# MSPM0G310X register map
Vendor: Texas Instruments; File version: This preliminary header file does not have a version number - build date: 2023-02-21 16:25:48
CPU: CM0 r0p1, little endian, MPU, no FPU, 3 interrupt priority bits
Registers are 32-bit, read-write, reset 0x0 unless marked. A register's access mark holds for its fields unless they carry their own. Offsets are from the block's base; [hi:lo] are bit positions; {n}, {i} and the like mark numbered series.

## ADC0 — PERIPHERALREGION
Base 0x40000000
Same registers: ADC1 0x40002000
0x400 FSUB_0 — Subscriber Configuration Register.
  [3:0] FSUB_0_CHANID — 0 = disconnected. 1-15 = connected to channelID = CHANID.
    0=FSUB_0_CHANID_UNCONNECTED (UNCONNECTED)
0x444 FPUB_1 — Publisher Configuration Register.
  [3:0] FPUB_1_CHANID — 0 = disconnected. 1-15 = connected to channelID = CHANID.
    0=FPUB_1_CHANID_UNCONNECTED (UNCONNECTED)
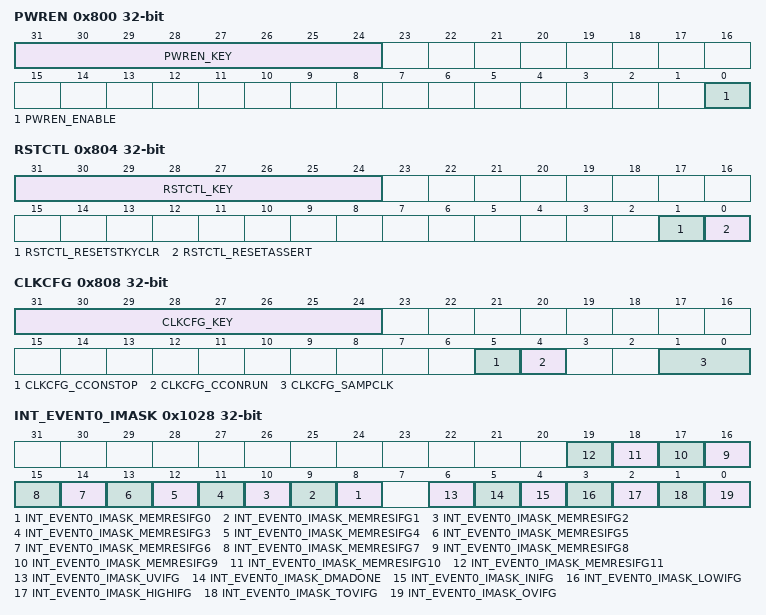
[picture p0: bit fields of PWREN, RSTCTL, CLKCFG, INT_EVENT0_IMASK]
0x800 PWREN — Power enable
  [31:24] PWREN_KEY wo — KEY to allow Power State Change
    38=PWREN_KEY_UNLOCK_W (_TO_UNLOCK_W_)
  [0] PWREN_ENABLE — Enable the power
    0=PWREN_ENABLE_DISABLE (DISABLE); 1=PWREN_ENABLE_ENABLE (ENABLE)
0x804 RSTCTL wo — Reset Control
  [31:24] RSTCTL_KEY — Unlock key
    177=RSTCTL_KEY_UNLOCK_W (_TO_UNLOCK_W_)
  [1] RSTCTL_RESETSTKYCLR — Clear the RESETSTKY bit in the STAT register
    0=RSTCTL_RESETSTKYCLR_NOP (NOP); 1=RSTCTL_RESETSTKYCLR_CLR (CLR)
  [0] RSTCTL_RESETASSERT — Assert reset to the peripheral
    0=RSTCTL_RESETASSERT_NOP (NOP); 1=RSTCTL_RESETASSERT_ASSERT (ASSERT)
0x808 CLKCFG — ADC clock configuration Register
  [31:24] CLKCFG_KEY wo — Unlock key
    169=CLKCFG_KEY_UNLOCK_W (_TO_UNLOCK_W_)
  [5] CLKCFG_CCONSTOP — CCONSTOP: Forces SYSOSC to run at base frequency when device is in STOP mode which can be used as ADC sample or conversion clock source.
    0=CLKCFG_CCONSTOP_DISABLE (DISABLE); 1=CLKCFG_CCONSTOP_ENABLE (ENABLE)
  [4] CLKCFG_CCONRUN — CCONRUN: Forces SYSOSC to run at base frequency when device is in RUN mode which can be used as ADC sample or conversion clock source.
    0=CLKCFG_CCONRUN_DISABLE (DISABLE); 1=CLKCFG_CCONRUN_ENABLE (ENABLE)
  [1:0] CLKCFG_SAMPCLK — ADC sample clock source selection.
    0=CLKCFG_SAMPCLK_SYSOSC (SYSOSC); 1=CLKCFG_SAMPCLK_ULPCLK (ULPCLK); 2=CLKCFG_SAMPCLK_HFCLK (HFCLK)
0x814 STAT ro — Status Register
  [16] STAT_RESETSTKY — This bit indicates, if the peripheral was reset, since this bit was cleared by RESETSTKYCLR in the RSTCTL register
    0=STAT_RESETSTKY_NORES (NORES); 1=STAT_RESETSTKY_RESET (RESET)
0x1020 INT_EVENT0_IIDX ro — Interrupt index
  [9:0] INT_EVENT0_IIDX_STAT — Interrupt index status
    0=INT_EVENT0_IIDX_STAT_NO_INTR (NO_INTR); 1=INT_EVENT0_IIDX_STAT_OVIFG (OVIFG); 2=INT_EVENT0_IIDX_STAT_TOVIFG (TOVIFG); 3=INT_EVENT0_IIDX_STAT_HIGHIFG (HIGHIFG); 4=INT_EVENT0_IIDX_STAT_LOWIFG (LOWIFG); 5=INT_EVENT0_IIDX_STAT_INIFG (INIFG); 6=INT_EVENT0_IIDX_STAT_DMADONE (DMADONE); 7=INT_EVENT0_IIDX_STAT_UVIFG (UVIFG); {v}=INT_EVENT0_IIDX_STAT_MEMRESIFG{v-9} (MEMRESIFG{v-9}) (v=9..32)
0x1028 INT_EVENT0_IMASK — Interrupt mask
  [n+8] INT_EVENT0_IMASK_MEMRESIFG{n} (n=0..11) — Raw interrupt status for MEMRES{n}. This bit is set to 1 when MEMRES{n} is loaded with a new conversion result. Reading MEMRES{n} register will clear this bit, or when the corresponding bit in ICLR is set to 1
    0=INT_EVENT0_IMASK_MEMRESIFG{n}_CLR (CLR); 1=INT_EVENT0_IMASK_MEMRESIFG{n}_SET (SET)
  [6] INT_EVENT0_IMASK_UVIFG — Raw interrupt flag for MEMRESx underflow. This bit is reset to 0 by IIDX read or when corresponding bit in ICLR is set to 1.
    0=INT_EVENT0_IMASK_UVIFG_CLR (CLR); 1=INT_EVENT0_IMASK_UVIFG_SET (SET)
  [5] INT_EVENT0_IMASK_DMADONE — Raw interrupt flag for DMADONE. This bit is reset to 0 by IIDX read or when corresponding bit in ICLR_EX is set to 1.
    0=INT_EVENT0_IMASK_DMADONE_CLR (CLR); 1=INT_EVENT0_IMASK_DMADONE_SET (SET)
  [4] INT_EVENT0_IMASK_INIFG — Mask INIFG in MIS_EX register.
    0=INT_EVENT0_IMASK_INIFG_CLR (CLR); 1=INT_EVENT0_IMASK_INIFG_SET (SET)
  [3] INT_EVENT0_IMASK_LOWIFG — Raw interrupt flag for the MEMRESx result register being below than the WCLOWx threshold of the window comparator. This bit is reset to 0 by IIDX read or when corresponding bit in ICLR_EX is set to 1.
    0=INT_EVENT0_IMASK_LOWIFG_CLR (CLR); 1=INT_EVENT0_IMASK_LOWIFG_SET (SET)
  [2] INT_EVENT0_IMASK_HIGHIFG — Raw interrupt flag for the MEMRESx result register being higher than the WCHIGHx threshold of the window comparator. This bit is reset to 0 by IIDX read or when corresponding bit in ICLR_EX is set to 1.
    0=INT_EVENT0_IMASK_HIGHIFG_CLR (CLR); 1=INT_EVENT0_IMASK_HIGHIFG_SET (SET)
  [1] INT_EVENT0_IMASK_TOVIFG — Raw interrupt flag for sequence conversion timeout overflow. This bit is reset to 0 by IIDX read or when corresponding bit in ICLR_EX is set to 1.
    0=INT_EVENT0_IMASK_TOVIFG_CLR (CLR); 1=INT_EVENT0_IMASK_TOVIFG_SET (SET)
  [0] INT_EVENT0_IMASK_OVIFG — Raw interrupt flag for MEMRESx overflow. This bit is reset to 0 by IIDX read or when corresponding bit in ICLR_EX is set to 1.
    0=INT_EVENT0_IMASK_OVIFG_CLR (CLR); 1=INT_EVENT0_IMASK_OVIFG_SET (SET)
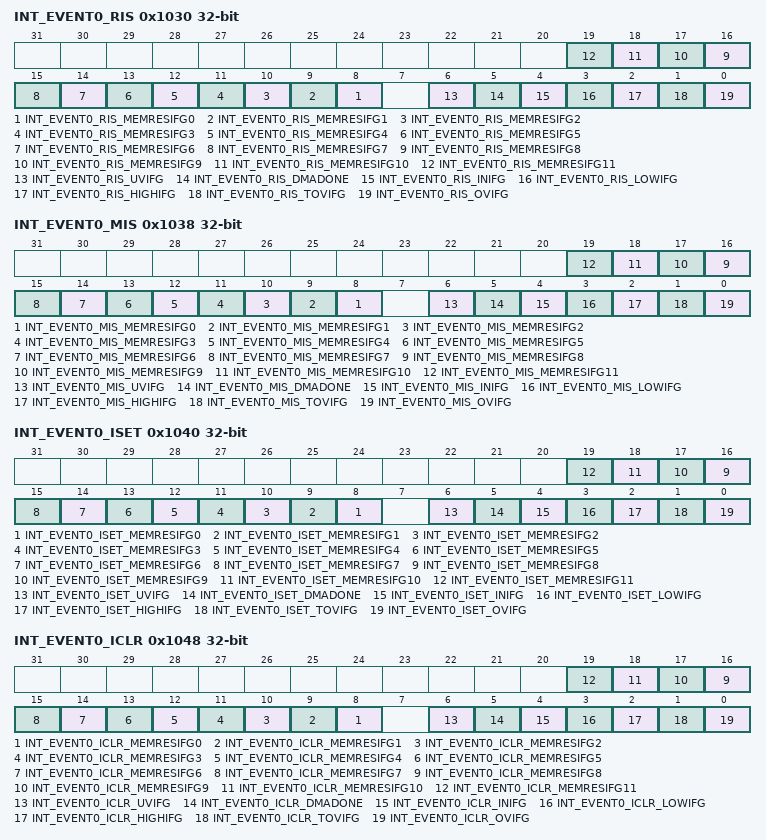
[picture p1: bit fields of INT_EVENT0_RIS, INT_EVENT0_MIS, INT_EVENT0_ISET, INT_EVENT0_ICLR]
0x1030 INT_EVENT0_RIS ro — Raw interrupt status
  [n+8] INT_EVENT0_RIS_MEMRESIFG{n} (n=0..11) — Raw interrupt status for MEMRES{n}. This bit is set to 1 when MEMRES{n} is loaded with a new conversion result. Reading MEMRES{n} register will clear this bit, or when the corresponding bit in ICLR is set to 1
    0=INT_EVENT0_RIS_MEMRESIFG{n}_CLR (CLR); 1=INT_EVENT0_RIS_MEMRESIFG{n}_SET (SET)
  [6] INT_EVENT0_RIS_UVIFG — Raw interrupt flag for MEMRESx underflow. This bit is reset to 0 by IIDX read or when corresponding bit in ICLR is set to 1.
    0=INT_EVENT0_RIS_UVIFG_CLR (CLR); 1=INT_EVENT0_RIS_UVIFG_SET (SET)
  [5] INT_EVENT0_RIS_DMADONE — Raw interrupt flag for DMADONE. This bit is reset to 0 by IIDX read or when corresponding bit in ICLR_EX is set to 1.
    0=INT_EVENT0_RIS_DMADONE_CLR (CLR); 1=INT_EVENT0_RIS_DMADONE_SET (SET)
  [4] INT_EVENT0_RIS_INIFG — Mask INIFG in MIS_EX register.
    0=INT_EVENT0_RIS_INIFG_CLR (CLR); 1=INT_EVENT0_RIS_INIFG_SET (SET)
  [3] INT_EVENT0_RIS_LOWIFG — Raw interrupt flag for the MEMRESx result register being below than the WCLOWx threshold of the window comparator. This bit is reset to 0 by IIDX read or when corresponding bit in ICLR_EX is set to 1.
    0=INT_EVENT0_RIS_LOWIFG_CLR (CLR); 1=INT_EVENT0_RIS_LOWIFG_SET (SET)
  [2] INT_EVENT0_RIS_HIGHIFG — Raw interrupt flag for the MEMRESx result register being higher than the WCHIGHx threshold of the window comparator. This bit is reset to 0 by IIDX read or when corresponding bit in ICLR_EX is set to 1.
    0=INT_EVENT0_RIS_HIGHIFG_CLR (CLR); 1=INT_EVENT0_RIS_HIGHIFG_SET (SET)
  [1] INT_EVENT0_RIS_TOVIFG — Raw interrupt flag for sequence conversion trigger overflow. This bit is reset to 0 by IIDX read or when corresponding bit in ICLR_EX is set to 1.
    0=INT_EVENT0_RIS_TOVIFG_CLR (CLR); 1=INT_EVENT0_RIS_TOVIFG_SET (SET)
  [0] INT_EVENT0_RIS_OVIFG — Raw interrupt flag for MEMRESx overflow. This bit is reset to 0 by IIDX read or when corresponding bit in ICLR_EX is set to 1.
    0=INT_EVENT0_RIS_OVIFG_CLR (CLR); 1=INT_EVENT0_RIS_OVIFG_SET (SET)
0x1038 INT_EVENT0_MIS ro — Masked interrupt status
  [n+8] INT_EVENT0_MIS_MEMRESIFG{n} (n=0..11) — Raw interrupt status for MEMRES{n}. This bit is set to 1 when MEMRES{n} is loaded with a new conversion result. Reading MEMRES{n} register will clear this bit, or when the corresponding bit in ICLR is set to 1
    0=INT_EVENT0_MIS_MEMRESIFG{n}_CLR (CLR); 1=INT_EVENT0_MIS_MEMRESIFG{n}_SET (SET)
  [6] INT_EVENT0_MIS_UVIFG — Raw interrupt flag for MEMRESx underflow. This bit is reset to 0 by IIDX read or when corresponding bit in ICLR is set to 1.
    0=INT_EVENT0_MIS_UVIFG_CLR (CLR); 1=INT_EVENT0_MIS_UVIFG_SET (SET)
  [5] INT_EVENT0_MIS_DMADONE — Raw interrupt flag for DMADONE. This bit is reset to 0 by IIDX read or when corresponding bit in ICLR_EX is set to 1.
    0=INT_EVENT0_MIS_DMADONE_CLR (CLR); 1=INT_EVENT0_MIS_DMADONE_SET (SET)
  [4] INT_EVENT0_MIS_INIFG — Mask INIFG in MIS_EX register.
    0=INT_EVENT0_MIS_INIFG_CLR (CLR); 1=INT_EVENT0_MIS_INIFG_SET (SET)
  [3] INT_EVENT0_MIS_LOWIFG — Raw interrupt flag for the MEMRESx result register being below than the WCLOWx threshold of the window comparator. This bit is reset to 0 by IIDX read or when corresponding bit in ICLR_EX is set to 1.
    0=INT_EVENT0_MIS_LOWIFG_CLR (CLR); 1=INT_EVENT0_MIS_LOWIFG_SET (SET)
  [2] INT_EVENT0_MIS_HIGHIFG — Raw interrupt flag for the MEMRESx result register being higher than the WCHIGHx threshold of the window comparator. This bit is reset to 0 by IIDX read or when corresponding bit in ICLR_EX is set to 1.
    0=INT_EVENT0_MIS_HIGHIFG_CLR (CLR); 1=INT_EVENT0_MIS_HIGHIFG_SET (SET)
  [1] INT_EVENT0_MIS_TOVIFG — Raw interrupt flag for sequence conversion timeout overflow. This bit is reset to 0 by IIDX read or when corresponding bit in ICLR_EX is set to 1.
    0=INT_EVENT0_MIS_TOVIFG_CLR (CLR); 1=INT_EVENT0_MIS_TOVIFG_SET (SET)
  [0] INT_EVENT0_MIS_OVIFG — Raw interrupt flag for MEMRESx overflow. This bit is reset to 0 by IIDX read or when corresponding bit in ICLR_EX is set to 1.
    0=INT_EVENT0_MIS_OVIFG_CLR (CLR); 1=INT_EVENT0_MIS_OVIFG_SET (SET)
0x1040 INT_EVENT0_ISET wo — Interrupt set
  [n+8] INT_EVENT0_ISET_MEMRESIFG{n} (n=0..11) — Raw interrupt status for MEMRES{n}. This bit is set to 1 when MEMRES{n} is loaded with a new conversion result. Reading MEMRES{n} register will clear this bit, or when the corresponding bit in ICLR is set to 1
    0=INT_EVENT0_ISET_MEMRESIFG{n}_NO_EFFECT (NO_EFFECT); 1=INT_EVENT0_ISET_MEMRESIFG{n}_SET (SET)
  [6] INT_EVENT0_ISET_UVIFG — Raw interrupt flag for MEMRESx underflow. This bit is reset to 0 by IIDX read or when corresponding bit in ICLR_EX is set to 1.
    0=INT_EVENT0_ISET_UVIFG_NO_EFFECT (NO_EFFECT); 1=INT_EVENT0_ISET_UVIFG_SET (SET)
  [5] INT_EVENT0_ISET_DMADONE — Raw interrupt flag for DMADONE. This bit is reset to 0 by IIDX read or when corresponding bit in ICLR_EX is set to 1.
    0=INT_EVENT0_ISET_DMADONE_NO_EFFECT (NO_EFFECT); 1=INT_EVENT0_ISET_DMADONE_SET (SET)
  [4] INT_EVENT0_ISET_INIFG — Mask INIFG in MIS_EX register.
    0=INT_EVENT0_ISET_INIFG_NO_EFFECT (NO_EFFECT); 1=INT_EVENT0_ISET_INIFG_SET (SET)
  [3] INT_EVENT0_ISET_LOWIFG — Raw interrupt flag for the MEMRESx result register being below than the WCLOWx threshold of the window comparator. This bit is reset to 0 by IIDX read or when corresponding bit in ICLR_EX is set to 1.
    0=INT_EVENT0_ISET_LOWIFG_NO_EFFECT (NO_EFFECT); 1=INT_EVENT0_ISET_LOWIFG_SET (SET)
  [2] INT_EVENT0_ISET_HIGHIFG — Raw interrupt flag for the MEMRESx result register being higher than the WCHIGHx threshold of the window comparator. This bit is reset to 0 by IIDX read or when corresponding bit in ICLR_EX is set to 1.
    0=INT_EVENT0_ISET_HIGHIFG_NO_EFFECT (NO_EFFECT); 1=INT_EVENT0_ISET_HIGHIFG_SET (SET)
  [1] INT_EVENT0_ISET_TOVIFG — Raw interrupt flag for sequence conversion timeout overflow. This bit is reset to 0 by IIDX read or when corresponding bit in ICLR_EX is set to 1.
    0=INT_EVENT0_ISET_TOVIFG_NO_EFFECT (NO_EFFECT); 1=INT_EVENT0_ISET_TOVIFG_SET (SET)
  [0] INT_EVENT0_ISET_OVIFG — Raw interrupt flag for MEMRESx overflow. This bit is reset to 0 by IIDX read or when corresponding bit in ICLR_EX is set to 1.
    0=INT_EVENT0_ISET_OVIFG_NO_EFFECT (NO_EFFECT); 1=INT_EVENT0_ISET_OVIFG_SET (SET)
0x1048 INT_EVENT0_ICLR wo — Interrupt clear
  [n+8] INT_EVENT0_ICLR_MEMRESIFG{n} (n=0..11) — Raw interrupt status for MEMRES{n}. This bit is set to 1 when MEMRES{n} is loaded with a new conversion result. Reading MEMRES{n} register will clear this bit, or when the corresponding bit in ICLR is set to 1
    0=INT_EVENT0_ICLR_MEMRESIFG{n}_NO_EFFECT (NO_EFFECT); 1=INT_EVENT0_ICLR_MEMRESIFG{n}_CLR (CLR)
  [6] INT_EVENT0_ICLR_UVIFG — Raw interrupt flag for MEMRESx underflow. This bit is reset to 0 by IIDX read or when corresponding bit in ICLR_EX is set to 1.
    0=INT_EVENT0_ICLR_UVIFG_NO_EFFECT (NO_EFFECT); 1=INT_EVENT0_ICLR_UVIFG_CLR (CLR)
  [5] INT_EVENT0_ICLR_DMADONE — Raw interrupt flag for DMADONE. This bit is reset to 0 by IIDX read or when corresponding bit in ICLR_EX is set to 1.
    0=INT_EVENT0_ICLR_DMADONE_NO_EFFECT (NO_EFFECT); 1=INT_EVENT0_ICLR_DMADONE_CLR (CLR)
  [4] INT_EVENT0_ICLR_INIFG — Mask INIFG in MIS_EX register.
    0=INT_EVENT0_ICLR_INIFG_NO_EFFECT (NO_EFFECT); 1=INT_EVENT0_ICLR_INIFG_CLR (CLR)
  [3] INT_EVENT0_ICLR_LOWIFG — Raw interrupt flag for the MEMRESx result register being below than the WCLOWx threshold of the window comparator. This bit is reset to 0 by IIDX read or when corresponding bit in ICLR_EX is set to 1.
    0=INT_EVENT0_ICLR_LOWIFG_NO_EFFECT (NO_EFFECT); 1=INT_EVENT0_ICLR_LOWIFG_CLR (CLR)
  [2] INT_EVENT0_ICLR_HIGHIFG — Raw interrupt flag for the MEMRESx result register being higher than the WCHIGHx threshold of the window comparator. This bit is reset to 0 by IIDX read or when corresponding bit in ICLR_EX is set to 1.
    0=INT_EVENT0_ICLR_HIGHIFG_NO_EFFECT (NO_EFFECT); 1=INT_EVENT0_ICLR_HIGHIFG_CLR (CLR)
  [1] INT_EVENT0_ICLR_TOVIFG — Raw interrupt flag for sequence conversion timeout overflow. This bit is reset to 0 by IIDX read or when corresponding bit in ICLR_EX is set to 1.
    0=INT_EVENT0_ICLR_TOVIFG_NO_EFFECT (NO_EFFECT); 1=INT_EVENT0_ICLR_TOVIFG_CLR (CLR)
  [0] INT_EVENT0_ICLR_OVIFG — Raw interrupt flag for MEMRESx overflow. This bit is reset to 0 by IIDX read or when corresponding bit in ICLR_EX is set to 1.
    0=INT_EVENT0_ICLR_OVIFG_NO_EFFECT (NO_EFFECT); 1=INT_EVENT0_ICLR_OVIFG_CLR (CLR)
0x1050 INT_EVENT1_IIDX ro — Interrupt index
  [9:0] INT_EVENT1_IIDX_STAT — Interrupt index status
    0=INT_EVENT1_IIDX_STAT_NO_INTR (NO_INTR); 3=INT_EVENT1_IIDX_STAT_HIGHIFG (HIGHIFG); 4=INT_EVENT1_IIDX_STAT_LOWIFG (LOWIFG); 5=INT_EVENT1_IIDX_STAT_INIFG (INIFG); 9=INT_EVENT1_IIDX_STAT_MEMRESIFG0 (MEMRESIFG0)
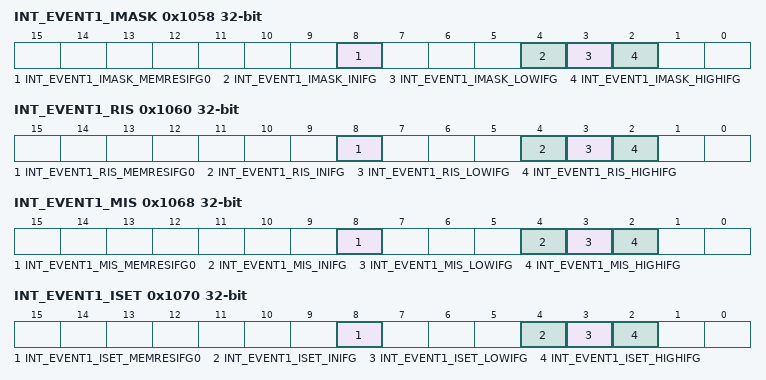
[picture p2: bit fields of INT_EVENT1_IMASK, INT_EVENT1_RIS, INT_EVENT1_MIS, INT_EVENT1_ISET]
0x1058 INT_EVENT1_IMASK — Interrupt mask
  [8] INT_EVENT1_IMASK_MEMRESIFG0 — Raw interrupt status for MEMRES0. This bit is set to 1 when MEMRES0 is loaded with a new conversion result. Reading MEMRES0 register will clear this bit, or when the corresponding bit in ICLR is set to 1
    0=INT_EVENT1_IMASK_MEMRESIFG0_CLR (CLR); 1=INT_EVENT1_IMASK_MEMRESIFG0_SET (SET)
  [4] INT_EVENT1_IMASK_INIFG — Mask INIFG in MIS_EX register.
    0=INT_EVENT1_IMASK_INIFG_CLR (CLR); 1=INT_EVENT1_IMASK_INIFG_SET (SET)
  [3] INT_EVENT1_IMASK_LOWIFG — Raw interrupt flag for the MEMRESx result register being below than the WCLOWx threshold of the window comparator. This bit is reset to 0 by IIDX read or when corresponding bit in ICLR_EX is set to 1.
    0=INT_EVENT1_IMASK_LOWIFG_CLR (CLR); 1=INT_EVENT1_IMASK_LOWIFG_SET (SET)
  [2] INT_EVENT1_IMASK_HIGHIFG — Raw interrupt flag for the MEMRESx result register being higher than the WCHIGHx threshold of the window comparator. This bit is reset to 0 by IIDX read or when corresponding bit in ICLR_EX is set to 1.
    0=INT_EVENT1_IMASK_HIGHIFG_CLR (CLR); 1=INT_EVENT1_IMASK_HIGHIFG_SET (SET)
0x1060 INT_EVENT1_RIS ro — Raw interrupt status
  [8] INT_EVENT1_RIS_MEMRESIFG0 — Raw interrupt status for MEMRES0. This bit is set to 1 when MEMRES0 is loaded with a new conversion result. Reading MEMRES0 register will clear this bit, or when the corresponding bit in ICLR is set to 1
    0=INT_EVENT1_RIS_MEMRESIFG0_CLR (CLR); 1=INT_EVENT1_RIS_MEMRESIFG0_SET (SET)
  [4] INT_EVENT1_RIS_INIFG — Mask INIFG in MIS_EX register.
    0=INT_EVENT1_RIS_INIFG_CLR (CLR); 1=INT_EVENT1_RIS_INIFG_SET (SET)
  [3] INT_EVENT1_RIS_LOWIFG — Raw interrupt flag for the MEMRESx result register being below than the WCLOWx threshold of the window comparator. This bit is reset to 0 by IIDX read or when corresponding bit in ICLR_EX is set to 1.
    0=INT_EVENT1_RIS_LOWIFG_CLR (CLR); 1=INT_EVENT1_RIS_LOWIFG_SET (SET)
  [2] INT_EVENT1_RIS_HIGHIFG — Raw interrupt flag for the MEMRESx result register being higher than the WCHIGHx threshold of the window comparator. This bit is reset to 0 by IIDX read or when corresponding bit in ICLR_EX is set to 1.
    0=INT_EVENT1_RIS_HIGHIFG_CLR (CLR); 1=INT_EVENT1_RIS_HIGHIFG_SET (SET)
0x1068 INT_EVENT1_MIS ro — Masked interrupt status
  [8] INT_EVENT1_MIS_MEMRESIFG0 — Raw interrupt status for MEMRES0. This bit is set to 1 when MEMRES0 is loaded with a new conversion result. Reading MEMRES0 register will clear this bit, or when the corresponding bit in ICLR is set to 1
    0=INT_EVENT1_MIS_MEMRESIFG0_CLR (CLR); 1=INT_EVENT1_MIS_MEMRESIFG0_SET (SET)
  [4] INT_EVENT1_MIS_INIFG — Mask INIFG in MIS_EX register.
    0=INT_EVENT1_MIS_INIFG_CLR (CLR); 1=INT_EVENT1_MIS_INIFG_SET (SET)
  [3] INT_EVENT1_MIS_LOWIFG — Raw interrupt flag for the MEMRESx result register being below than the WCLOWx threshold of the window comparator. This bit is reset to 0 by IIDX read or when corresponding bit in ICLR_EX is set to 1.
    0=INT_EVENT1_MIS_LOWIFG_CLR (CLR); 1=INT_EVENT1_MIS_LOWIFG_SET (SET)
  [2] INT_EVENT1_MIS_HIGHIFG — Raw interrupt flag for the MEMRESx result register being higher than the WCHIGHx threshold of the window comparator. This bit is reset to 0 by IIDX read or when corresponding bit in ICLR_EX is set to 1.
    0=INT_EVENT1_MIS_HIGHIFG_CLR (CLR); 1=INT_EVENT1_MIS_HIGHIFG_SET (SET)
0x1070 INT_EVENT1_ISET wo — Interrupt set
  [8] INT_EVENT1_ISET_MEMRESIFG0 — Raw interrupt status for MEMRES0. This bit is set to 1 when MEMRES0 is loaded with a new conversion result. Reading MEMRES0 register will clear this bit, or when the corresponding bit in ICLR is set to 1
    0=INT_EVENT1_ISET_MEMRESIFG0_NO_EFFECT (NO_EFFECT); 1=INT_EVENT1_ISET_MEMRESIFG0_SET (SET)
  [4] INT_EVENT1_ISET_INIFG — Mask INIFG in MIS_EX register.
    0=INT_EVENT1_ISET_INIFG_NO_EFFECT (NO_EFFECT); 1=INT_EVENT1_ISET_INIFG_SET (SET)
  [3] INT_EVENT1_ISET_LOWIFG — Raw interrupt flag for the MEMRESx result register being below than the WCLOWx threshold of the window comparator. This bit is reset to 0 by IIDX read or when corresponding bit in ICLR_EX is set to 1.
    0=INT_EVENT1_ISET_LOWIFG_NO_EFFECT (NO_EFFECT); 1=INT_EVENT1_ISET_LOWIFG_SET (SET)
  [2] INT_EVENT1_ISET_HIGHIFG — Raw interrupt flag for the MEMRESx result register being higher than the WCHIGHx threshold of the window comparator. This bit is reset to 0 by IIDX read or when corresponding bit in ICLR_EX is set to 1.
    0=INT_EVENT1_ISET_HIGHIFG_NO_EFFECT (NO_EFFECT); 1=INT_EVENT1_ISET_HIGHIFG_SET (SET)
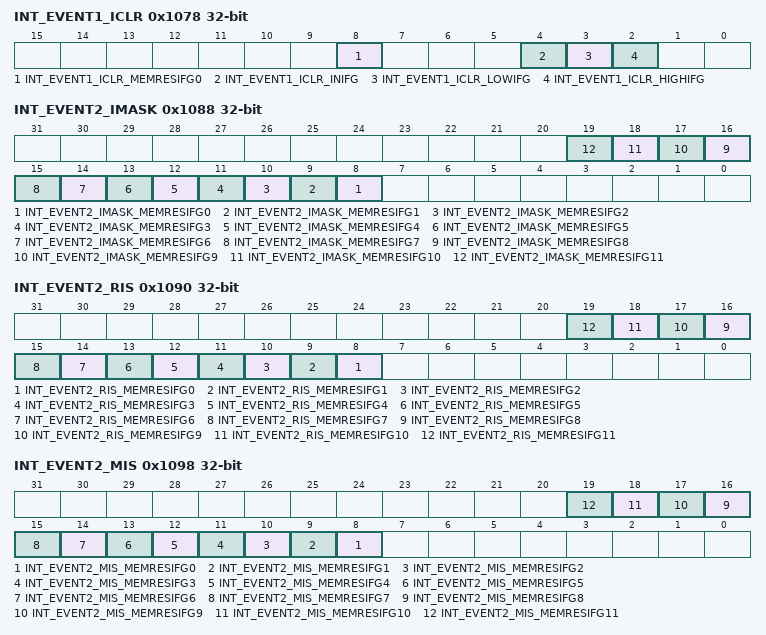
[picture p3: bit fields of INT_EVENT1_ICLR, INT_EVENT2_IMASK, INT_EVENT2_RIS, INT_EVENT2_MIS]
0x1078 INT_EVENT1_ICLR wo — Interrupt clear
  [8] INT_EVENT1_ICLR_MEMRESIFG0 — Raw interrupt status for MEMRES0. This bit is set to 1 when MEMRES0 is loaded with a new conversion result. Reading MEMRES0 register will clear this bit, or when the corresponding bit in ICLR is set to 1
    0=INT_EVENT1_ICLR_MEMRESIFG0_NO_EFFECT (NO_EFFECT); 1=INT_EVENT1_ICLR_MEMRESIFG0_CLR (CLR)
  [4] INT_EVENT1_ICLR_INIFG — Mask INIFG in MIS_EX register.
    0=INT_EVENT1_ICLR_INIFG_NO_EFFECT (NO_EFFECT); 1=INT_EVENT1_ICLR_INIFG_CLR (CLR)
  [3] INT_EVENT1_ICLR_LOWIFG — Raw interrupt flag for the MEMRESx result register being below than the WCLOWx threshold of the window comparator. This bit is reset to 0 by IIDX read or when corresponding bit in ICLR_EX is set to 1.
    0=INT_EVENT1_ICLR_LOWIFG_NO_EFFECT (NO_EFFECT); 1=INT_EVENT1_ICLR_LOWIFG_CLR (CLR)
  [2] INT_EVENT1_ICLR_HIGHIFG — Raw interrupt flag for the MEMRESx result register being higher than the WCHIGHx threshold of the window comparator. This bit is reset to 0 by IIDX read or when corresponding bit in ICLR_EX is set to 1.
    0=INT_EVENT1_ICLR_HIGHIFG_NO_EFFECT (NO_EFFECT); 1=INT_EVENT1_ICLR_HIGHIFG_CLR (CLR)
0x1080 INT_EVENT2_IIDX ro — Interrupt index
  [9:0] INT_EVENT2_IIDX_STAT — Interrupt index status
    0=INT_EVENT2_IIDX_STAT_NO_INTR (NO_INTR); {v}=INT_EVENT2_IIDX_STAT_MEMRESIFG{v-9} (MEMRESIFG{v-9}) (v=9..32)
0x1088 INT_EVENT2_IMASK — Interrupt mask extension
  [n+8] INT_EVENT2_IMASK_MEMRESIFG{n} (n=0..11) — Raw interrupt status for MEMRES{n}. This bit is set to 1 when MEMRES{n} is loaded with a new conversion result. Reading MEMRES{n} register will clear this bit, or when the corresponding bit in ICLR is set to 1
    0=INT_EVENT2_IMASK_MEMRESIFG{n}_CLR (CLR); 1=INT_EVENT2_IMASK_MEMRESIFG{n}_SET (SET)
0x1090 INT_EVENT2_RIS ro — Raw interrupt status extension
  [n+8] INT_EVENT2_RIS_MEMRESIFG{n} (n=0..11) — Raw interrupt status for MEMRES{n}. This bit is set to 1 when MEMRES{n} is loaded with a new conversion result. Reading MEMRES{n} register will clear this bit, or when the corresponding bit in ICLR is set to 1
    0=INT_EVENT2_RIS_MEMRESIFG{n}_CLR (CLR); 1=INT_EVENT2_RIS_MEMRESIFG{n}_SET (SET)
0x1098 INT_EVENT2_MIS ro — Masked interrupt status extension
  [n+8] INT_EVENT2_MIS_MEMRESIFG{n} (n=0..11) — Raw interrupt status for MEMRES{n}. This bit is set to 1 when MEMRES{n} is loaded with a new conversion result. Reading MEMRES{n} register will clear this bit, or when the corresponding bit in ICLR is set to 1
    0=INT_EVENT2_MIS_MEMRESIFG{n}_CLR (CLR); 1=INT_EVENT2_MIS_MEMRESIFG{n}_SET (SET)
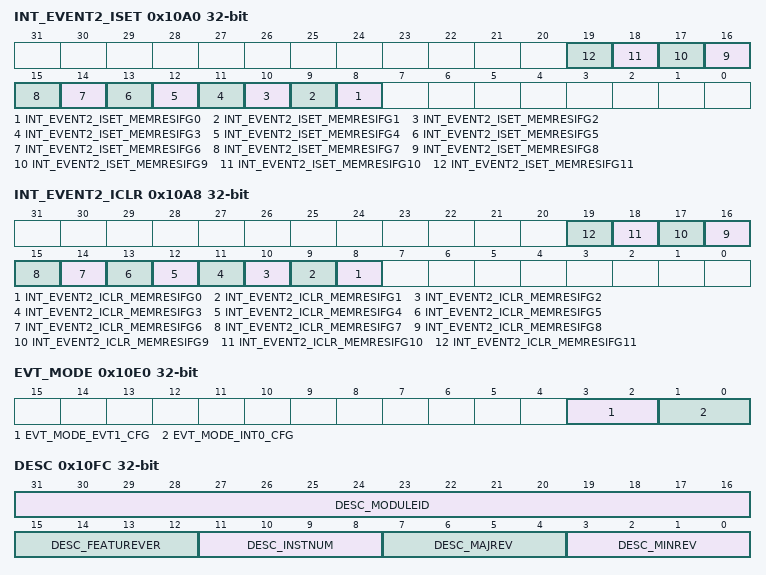
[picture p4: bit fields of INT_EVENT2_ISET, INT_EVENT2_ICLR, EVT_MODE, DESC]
0x10A0 INT_EVENT2_ISET wo — Interrupt set extension
  [n+8] INT_EVENT2_ISET_MEMRESIFG{n} (n=0..11) — Raw interrupt status for MEMRES{n}. This bit is set to 1 when MEMRES{n} is loaded with a new conversion result. Reading MEMRES{n} register will clear this bit, or when the corresponding bit in ICLR is set to 1
    0=INT_EVENT2_ISET_MEMRESIFG{n}_NO_EFFECT (NO_EFFECT); 1=INT_EVENT2_ISET_MEMRESIFG{n}_SET (SET)
0x10A8 INT_EVENT2_ICLR wo — Interrupt clear extension
  [n+8] INT_EVENT2_ICLR_MEMRESIFG{n} (n=0..11) — Raw interrupt status for MEMRES{n}. This bit is set to 1 when MEMRES{n} is loaded with a new conversion result. Reading MEMRES{n} register will clear this bit, or when the corresponding bit in ICLR is set to 1
    0=INT_EVENT2_ICLR_MEMRESIFG{n}_NO_EFFECT (NO_EFFECT); 1=INT_EVENT2_ICLR_MEMRESIFG{n}_CLR (CLR)
0x10E0 EVT_MODE ro — Event Mode
  [3:2] EVT_MODE_EVT1_CFG — Event line mode select for event corresponding to IPSTANDARD.INT_EVENT1
    0=EVT_MODE_EVT1_CFG_DISABLE (DISABLE); 1=EVT_MODE_EVT1_CFG_SOFTWARE (SOFTWARE); 2=EVT_MODE_EVT1_CFG_HARDWARE (HARDWARE)
  [1:0] EVT_MODE_INT0_CFG — Event line mode select for event corresponding to IPSTANDARD.INT_EVENT0
    0=EVT_MODE_INT0_CFG_DISABLE (DISABLE); 1=EVT_MODE_INT0_CFG_SOFTWARE (SOFTWARE); 2=EVT_MODE_INT0_CFG_HARDWARE (HARDWARE)
0x10FC DESC ro — Module Description
  [31:16] DESC_MODULEID — Module identification contains a unique peripheral identification number. The assignments are maintained in a central database for all of the platform modules to ensure uniqueness.
  [15:12] DESC_FEATUREVER — Feature Set for the module *instance*
  [11:8] DESC_INSTNUM — Instance Number within the device. This will be a parameter to the RTL for modules that can have multiple instances
  [7:4] DESC_MAJREV — Major rev of the IP
  [3:0] DESC_MINREV — Minor rev of the IP
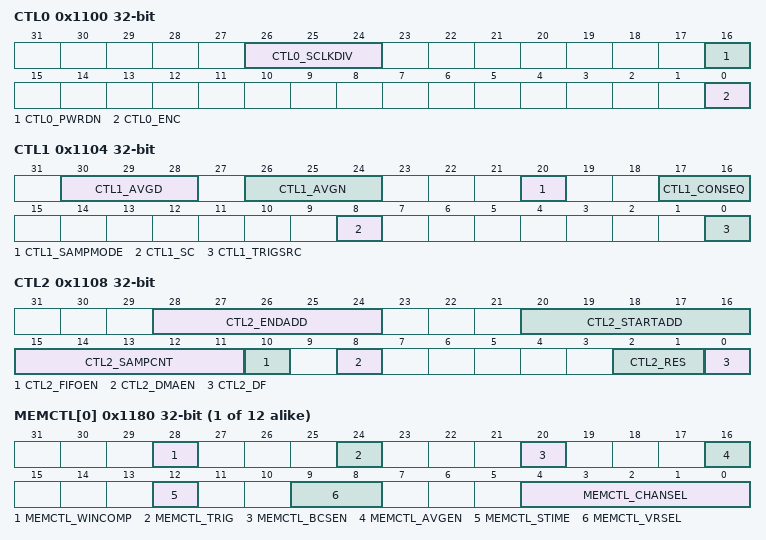
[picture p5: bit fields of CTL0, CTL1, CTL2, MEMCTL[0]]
0x1100 CTL0 — Control Register 0
  [26:24] CTL0_SCLKDIV — Sample clock divider
    0=CTL0_SCLKDIV_DIV_BY_1 (DIV_BY_1); 1=CTL0_SCLKDIV_DIV_BY_2 (DIV_BY_2); 2=CTL0_SCLKDIV_DIV_BY_4 (DIV_BY_4); 3=CTL0_SCLKDIV_DIV_BY_8 (DIV_BY_8); 4=CTL0_SCLKDIV_DIV_BY_16 (DIV_BY_16); 5=CTL0_SCLKDIV_DIV_BY_24 (DIV_BY_24); 6=CTL0_SCLKDIV_DIV_BY_32 (DIV_BY_32); 7=CTL0_SCLKDIV_DIV_BY_48 (DIV_BY_48)
  [16] CTL0_PWRDN — Power down policy
    0=CTL0_PWRDN_AUTO (AUTO); 1=CTL0_PWRDN_MANUAL (MANUAL)
  [0] CTL0_ENC — Enable conversion
    0=CTL0_ENC_OFF (OFF); 1=CTL0_ENC_ON (ON)
0x1104 CTL1 — Control Register 1
  [30:28] CTL1_AVGD — Hardware averager denominator. The number to divide the accumulated value by (this is a shift). Note result register is maximum of 16-bits long so if not shifted appropirately result will be truncated.
    {v}=CTL1_AVGD_SHIFT{v} (SHIFT{v}) (v=0..7)
  [26:24] CTL1_AVGN — Hardware averager numerator. Selects number of conversions to accumulate for current MEMCTLx and then it is divided by AVGD. Result will be stored in MEMRESx.
    0=CTL1_AVGN_DISABLE (DISABLE); 1=CTL1_AVGN_AVG_2 (AVG_2); 2=CTL1_AVGN_AVG_4 (AVG_4); 3=CTL1_AVGN_AVG_8 (AVG_8); 4=CTL1_AVGN_AVG_16 (AVG_16); 5=CTL1_AVGN_AVG_32 (AVG_32); 6=CTL1_AVGN_AVG_64 (AVG_64); 7=CTL1_AVGN_AVG_128 (AVG_128)
  [20] CTL1_SAMPMODE — Sample mode. This bit selects the source of the sampling signal. MANUAL option is not valid when TRIGSRC is selected as hardware event trigger.
    0=CTL1_SAMPMODE_AUTO (AUTO); 1=CTL1_SAMPMODE_MANUAL (MANUAL)
  [17:16] CTL1_CONSEQ — Conversion sequence mode
    0=CTL1_CONSEQ_SINGLE (SINGLE); 1=CTL1_CONSEQ_SEQUENCE (SEQUENCE); 2=CTL1_CONSEQ_REPEATSINGLE (REPEATSINGLE); 3=CTL1_CONSEQ_REPEATSEQUENCE (REPEATSEQUENCE)
  [8] CTL1_SC — Start of conversion
    0=CTL1_SC_STOP (STOP); 1=CTL1_SC_START (START)
  [0] CTL1_TRIGSRC — Sample trigger source
    0=CTL1_TRIGSRC_SOFTWARE (SOFTWARE); 1=CTL1_TRIGSRC_EVENT (EVENT)
0x1108 CTL2 — Control Register 2
  [28:24] CTL2_ENDADD — Sequence end address. These bits select which MEMCTLx is the last one for the sequence mode. The value of ENDADD is 0x00 to 0x17, corresponding to MEMRES0 to MEMRES23.
    {v}=CTL2_ENDADD_ADDR_{v:02} (ADDR_{v:02}) (v=0..23)
  [20:16] CTL2_STARTADD — Sequencer start address. These bits select which MEMCTLx is used for single conversion or as first MEMCTL for sequence mode. The value of STARTADD is 0x00 to 0x17, corresponding to MEMRES0 to MEMRES23.
    {v}=CTL2_STARTADD_ADDR_{v:02} (ADDR_{v:02}) (v=0..23)
  [15:11] CTL2_SAMPCNT — Number of ADC converted samples to be transferred on a DMA trigger
    0=CTL2_SAMPCNT_MIN (MIN); 24=CTL2_SAMPCNT_MAX (MAX)
  [10] CTL2_FIFOEN — Enable FIFO based operation
    0=CTL2_FIFOEN_DISABLE (DISABLE); 1=CTL2_FIFOEN_ENABLE (ENABLE)
  [8] CTL2_DMAEN — Enable DMA trigger for data transfer. Note: DMAEN bit is cleared by hardware based on DMA done signal at the end of data transfer. Software has to re-enable DMAEN bit for ADC to generate DMA triggers.
    0=CTL2_DMAEN_DISABLE (DISABLE); 1=CTL2_DMAEN_ENABLE (ENABLE)
  [2:1] CTL2_RES — Resolution. These bits define the resolutoin of ADC conversion result. Note : A value of 3 defaults to 12-bits resolution.
    0=CTL2_RES_BIT_12 (BIT_12); 1=CTL2_RES_BIT_10 (BIT_10); 2=CTL2_RES_BIT_8 (BIT_8)
  [0] CTL2_DF — Data read-back format. Data is always stored in binary unsigned format.
    0=CTL2_DF_UNSIGNED (UNSIGNED); 1=CTL2_DF_SIGNED (SIGNED)
0x1110 CLKFREQ — Sample Clock Frequency Range Register
  [2:0] CLKFREQ_FRANGE — Frequency Range.
    0=CLKFREQ_FRANGE_RANGE1TO4 (RANGE1TO4); 1=CLKFREQ_FRANGE_RANGE4TO8 (RANGE4TO8); 2=CLKFREQ_FRANGE_RANGE8TO16 (RANGE8TO16); 3=CLKFREQ_FRANGE_RANGE16TO20 (RANGE16TO20); 4=CLKFREQ_FRANGE_RANGE20TO24 (RANGE20TO24); 5=CLKFREQ_FRANGE_RANGE24TO32 (RANGE24TO32); 6=CLKFREQ_FRANGE_RANGE32TO40 (RANGE32TO40); 7=CLKFREQ_FRANGE_RANGE40TO48 (RANGE40TO48)
0x1114 SCOMP0 — Sample Time Compare 0 Register
  [9:0] SCOMP0_VAL — Specifies the number of sample clocks. When VAL = 0 or 1, number of sample clocks = Sample clock divide value. When VAL > 1, number of sample clocks = VAL x Sample clock divide value. Note: Sample clock divide value is not the value written to SCLKDIV but the actual divide value (SCLKDIV = 2 implies divide value is 4). Example: VAL = 4, SCLKDIV = 3 implies 32 sample clock cycles.
0x1118 SCOMP1 — Sample Time Compare 1 Register
  [9:0] SCOMP1_VAL — Specifies the number of sample clocks. When VAL = 0 or 1, number of sample clocks = Sample clock divide value. When VAL > 1, number of sample clocks = VAL x Sample clock divide value. Note: Sample clock divide value is not the value written to SCLKDIV but the actual divide value (SCLKDIV = 2 implies divide value is 4). Example: VAL = 4, SCLKDIV = 3 implies 32 sample clock cycles.
0x1148 WCLOW — Window Comparator Low Threshold Register
  [15:0] WCLOW_DATA — If DF = 0, unsigned binary format has to be used. The value based on the resolution has to be right aligned with the MSB on the left. For 10-bits and 8-bits resolution, unused bits have to be 0s. If DF = 1, 2s-complement format has to be used. The value based on the resolution has to be left aligned with the LSB on the right. For 10-bits and 8-bits resolution, unused bits have to be 0s.
0x1150 WCHIGH — Window Comparator High Threshold Register
  [15:0] WCHIGH_DATA — If DF = 0, unsigned binary format has to be used. The threshold value has to be right aligned, with the MSB on the left. For 10-bits and 8-bits resolution, unused bit have to be 0s. If DF = 1, 2s-complement format has to be used. The value based on the resolution has to be left aligned with the LSB on the right. For 10-bits and 8-bits resolution, unused bit have to be 0s.
{0x1180+4i} MEMCTL[{i}] (i=0..11) — Conversion Memory Control Register
  [28] MEMCTL_WINCOMP — Enable window comparator.
    0=MEMCTL_WINCOMP_DISABLE (DISABLE); 1=MEMCTL_WINCOMP_ENABLE (ENABLE)
  [24] MEMCTL_TRIG — Trigger policy. Indicates if a trigger will be needed to step to the next MEMCTL in the sequence or to perform next conversion in the case of repeat single channel conversions.
    0=MEMCTL_TRIG_AUTO_NEXT (AUTO_NEXT); 1=MEMCTL_TRIG_TRIGGER_NEXT (TRIGGER_NEXT)
  [20] MEMCTL_BCSEN — Enable burn out current source.
    0=MEMCTL_BCSEN_DISABLE (DISABLE); 1=MEMCTL_BCSEN_ENABLE (ENABLE)
  [16] MEMCTL_AVGEN — Enable hardware averaging.
    0=MEMCTL_AVGEN_DISABLE (DISABLE); 1=MEMCTL_AVGEN_ENABLE (ENABLE)
  [12] MEMCTL_STIME — Selects the source of sample timer period between SCOMP0 and SCOMP1.
    0=MEMCTL_STIME_SEL_SCOMP0 (SEL_SCOMP0); 1=MEMCTL_STIME_SEL_SCOMP1 (SEL_SCOMP1)
  [9:8] MEMCTL_VRSEL — Voltage reference selection. VEREFM must be connected to on-board ground when external reference option is selected. Note: Writing value 0x3 defaults to INTREF.
    0=MEMCTL_VRSEL_VDDA (VDDA); 1=MEMCTL_VRSEL_EXTREF (EXTREF); 2=MEMCTL_VRSEL_INTREF (INTREF)
  [4:0] MEMCTL_CHANSEL — Input channel select.
    {v}=MEMCTL_CHANSEL_CHAN_{v} (CHAN_{v}) (v=0..31)
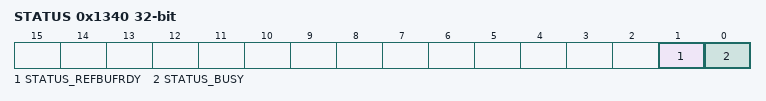
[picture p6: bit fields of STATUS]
0x1340 STATUS ro
  [1] STATUS_REFBUFRDY — Indicates reference buffer is powered up and ready.
    0=STATUS_REFBUFRDY_NOTREADY (NOTREADY); 1=STATUS_REFBUFRDY_READY (READY)
  [0] STATUS_BUSY — Busy. This bit indicates that an active ADC sample or conversion operation is in progress.
    0=STATUS_BUSY_IDLE (IDLE); 1=STATUS_BUSY_ACTIVE (ACTIVE)
